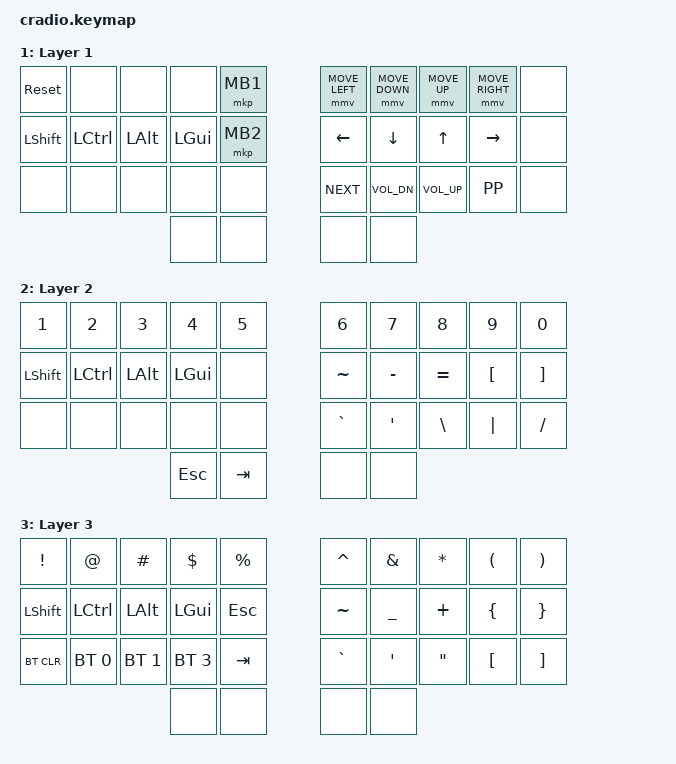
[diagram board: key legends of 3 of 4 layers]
// Copyright (c) 2022 The ZMK Contributors
// SPDX-License-Identifier: MIT

#include <behaviors.dtsi>
#include <dt-bindings/zmk/keys.h>
#include <dt-bindings/zmk/bt.h>
#include <dt-bindings/zmk/pointing.h>

// Home row mods macro
#define HRML(k1,k2,k3,k4) &ht LSHFT k1  &ht LCTRL k2  &ht LALT k3  &ht LGUI k4
#define HRMR(k1,k2,k3,k4) &ht RGUI k1  &ht LALT k2  &ht RCTRL k3  &ht RSHFT k4
#define MEH(k1) &ht LS(LC(LALT)) k1

/ {
    behaviors {
        ht: hold_tap {
            compatible = "zmk,behavior-hold-tap";
            #binding-cells = <2>;
            flavor = "balanced";
            tapping-term-ms = <220>;
            quick-tap-ms = <150>;
            require-prior-idle-ms = <100>;
            bindings = <&kp>, <&kp>;
        };
    };

    keymap {
        compatible = "zmk,keymap";
        default_layer {
            display-name = "Default Layer";
            bindings = <
        //╭──────────┬──────────┬──────────┬──────────┬──────────╮   ╭──────────┬──────────┬──────────┬──────────┬──────────╮
        //│  Q       │  W       │  E       │  R       │  T       │   │  Y       │  U       │  I       │  O       │  P       │
            &kp Q      &kp W      &kp E      &kp R      &kp T          &kp Y      &kp U      &kp I      &kp O      &kp P
        //├──────────┼──────────┼──────────┼──────────┼──────────┤   ├──────────┼──────────┼──────────┼──────────┼──────────┤
        //│  A       │  S       │  D       │  F       │  G       │   │  H       │  J       │  K       │  L       │ ' "      │
            HRML(A,        S,         D,         F)     &kp G          &kp H      HRMR(J,        K,         L,       SEMI)
        //├──────────┼──────────┼──────────┼──────────┼──────────┤   ├──────────┼──────────┼──────────┼──────────┼──────────┤
        //│  Z       │  X       │  C       │  V       │  B       │   │  N       │  M       │ , <      │ . >      │ / ?      │
            &kp Z      &kp X      &kp C      &kp V      &kp B          &kp N      &kp M      &kp COMMA  &kp DOT    &kp FSLH
        //╰──────────┴──────────┴──────────┼──────────┼──────────┤   ├──────────┼──────────┼──────────┴──────────┴──────────╯
                                            &lt 3 DEL  MEH(ENTER)     &lt 1 SPACE &lt 2 BSPC
        //                                 ╰──────────┴──────────╯   ╰──────────┴──────────╯
            >;
        };

        layer1 {
            display-name = "Layer 1";
            bindings = <
        //╭──────────┬──────────┬──────────┬──────────┬──────────╮   ╭──────────┬──────────┬──────────┬──────────┬──────────╮
        //│  RESET   │          │          │          │  Mouse 1 │   │  Mouse L │  Mouse D │  Mouse U │  Mouse R │          │
            &sys_reset &none      &none      &none      &mkp MB1       &mmv MOVE_LEFT &mmv MOVE_DOWN &mmv MOVE_UP &mmv MOVE_RIGHT &none 
        //├──────────┼──────────┼──────────┼──────────┼──────────┤   ├──────────┼──────────┼──────────┼──────────┼──────────┤
        //│  SHIFT   │  CTRL    │  ALT     │  GUI     │  Mouse 2 │   │  LEFT    │  DOWN    │  UP      │  RIGHT   │          │
            &kp LSHFT  &kp LCTRL  &kp LALT   &kp LGUI   &mkp MB2       &kp LEFT   &kp DOWN   &kp UP     &kp RIGHT   &none
        //├──────────┼──────────┼──────────┼──────────┼──────────┤   ├──────────┼──────────┼──────────┼──────────┼──────────┤
        //│          │          │          │          │          │   │          │          │          │          │          │
            &none      &none      &none      &none      &none          &kp K_NEXT &kp K_VOL_DN &kp K_VOL_UP &kp K_PP &none
        //╰──────────┴──────────┴──────────┼──────────┼──────────┤   ├──────────┼──────────┼──────────┴──────────┴──────────╯
                                             &none      &none          &none      &none 
        //                                 ╰──────────┴──────────╯   ╰──────────┴──────────╯
            >;
        };

        layer2 {
            display-name = "Layer 2";
            bindings = <
        //╭──────────┬──────────┬──────────┬──────────┬──────────╮   ╭──────────┬──────────┬──────────┬──────────┬──────────╮
        //│  1       │  2       │  3       │  4       │  5       │   │  6       │  7       │  8       │  9       │  0       │
            &kp N1     &kp N2     &kp N3     &kp N4     &kp N5         &kp N6     &kp N7     &kp N8     &kp N9     &kp N0
        //├──────────┼──────────┼──────────┼──────────┼──────────┤   ├──────────┼──────────┼──────────┼──────────┼──────────┤
        //│  SHIFT   │  CTRL    │  ALT     │  LGUI    │          │   │  ~       │  -       │  =       │  [       │  ]       │
            &kp LSHFT  &kp LCTRL  &kp LALT   &kp LGUI   &none          &kp TILDE  &kp MINUS  &kp EQUAL  &kp LBKT   &kp RBKT
        //├──────────┼──────────┼──────────┼──────────┼──────────┤   ├──────────┼──────────┼──────────┼──────────┼──────────┤
        //│          │          │          │          │          │   │  `       │  '       │  \       │  │       │  /       │
            &none      &none      &none      &none      &none          &kp GRAVE  &kp SQT    &kp BSLH   &kp PIPE   &kp FSLH
        //╰──────────┴──────────┴──────────┼──────────┼──────────┤   ├──────────┼──────────┼──────────┴──────────┴──────────╯
                                             &kp ESC    &kp TAB        &none      &none
        //                                 ╰──────────┴──────────╯   ╰──────────┴──────────╯
            >;
        };

        layer3 {
            display-name = "Layer 3";
            bindings = <
        //╭──────────┬──────────┬──────────┬──────────┬──────────╮   ╭──────────┬──────────┬──────────┬──────────┬──────────╮
        //│  !       │  @       │  #       │  $       │  %       │   │  ^       │  &       │  *       │  (       │  )       │
            &kp EXCL   &kp AT     &kp HASH   &kp DLLR   &kp PRCNT      &kp CARET  &kp AMPS   &kp ASTRK  &kp LPAR   &kp RPAR
        //├──────────┼──────────┼──────────┼──────────┼──────────┤   ├──────────┼──────────┼──────────┼──────────┼──────────┤
        //│  SHIFT   │  CTRL    │  ALT     │  LGUI    │  ESC     │   │  ~       │  _       │  +       │  {       │  }       │
            &kp LSHFT  &kp LCTRL  &kp LALT   &kp LGUI   &kp ESC        &kp TILDE  &kp UNDER  &kp PLUS   &kp LBRC   &kp RBRC
        //├──────────┼──────────┼──────────┼──────────┼──────────┤   ├──────────┼──────────┼──────────┼──────────┼──────────┤
        //│ BT CLEAR │ BT 0     │ BT 1     │ BT 2     │  TAB     │   │  `       │  '       │  "       │  [       │  ]       │
            &bt BT_CLR &bt BT_SEL 0 &bt BT_SEL 1 &bt BT_SEL 3 &kp TAB        &kp GRAVE  &kp SQT    &kp DQT    &kp LBKT   &kp RBKT
        //╰──────────┴──────────┴──────────┼──────────┼──────────┤   ├──────────┼──────────┼──────────┴──────────┴──────────╯
                                             &none      &none          &none      &none
        //                                 ╰──────────┴──────────╯   ╰──────────┴──────────╯
            >;
        };
    };
};
